AUTOSAR XML (schema 4-2-2)
package /Components
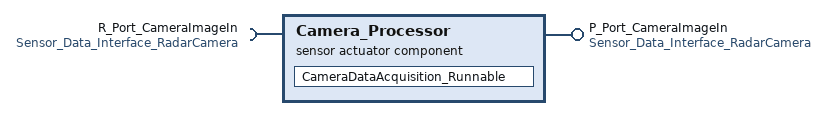
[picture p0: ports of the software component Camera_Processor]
  sensor actuator sw component type Camera_Processor
    provide port P_Port_CameraImageIn: provided-interface=Sensor_Data_Interface_RadarCamera
    require port R_Port_CameraImageIn: required-interface=Sensor_Data_Interface_RadarCamera
    behavior CameraDataProcessing_BHV
      data received event CameraImageReady: start-on-event=CameraDataAcquisition_Runnable
      data send completed event CameraImageSent: start-on-event=CameraDataAcquisition_Runnable, event-source=CameraImageOutput
      runnable CameraDataAcquisition_Runnable: symbol=CameraDataAcquisition_Runnable_Symbol
        data-receive-point-by-arguments:
          access CameraImageInput: accessed-variable={autosar-variable-in-impl-datatype={port-prototype=R_Port_CameraImageIn, target-data-prototype=CameraImageData}, autosar-variable=R_Port_CameraImageIn.CameraImageData}
        data-send-points:
          access CameraImageOutput: accessed-variable={autosar-variable-in-impl-datatype={port-prototype=P_Port_CameraImageIn, target-data-prototype=CameraImageData}, autosar-variable=P_Port_CameraImageIn.CameraImageData}
